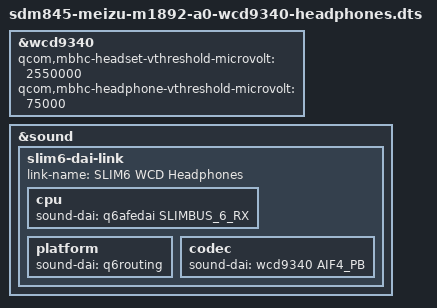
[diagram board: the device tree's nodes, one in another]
// SPDX-License-Identifier: GPL-2.0-only
/*
 * M1892 A0.7g: connect Multimedia1 to the stock Flyme headphone backend.
 *
 * Flyme 7.1.3.4A identifies the built-in 3.5-mm output as
 * SLIMBUS_6_RX -> WCD9340 AIF4_PB, using codec RX2/RX3.  Keep only that
 * playback backend in this diagnostic card so the SDM845 machine driver's
 * one-time SLIMbus channel-map setup is applied to AIF4, not AIF1.
 * Capture and both CS35L41 speaker amplifiers remain disabled.
 */

/dts-v1/;

#include <dt-bindings/sound/qcom,q6afe.h>
#include <dt-bindings/sound/qcom,wcd934x.h>

#include "sdm845-meizu-m1892-a0-minimal-card.dts"

&wcd9340 {
	/* Values measured from the stock M1892 downstream DT. */
	qcom,mbhc-headset-vthreshold-microvolt = <2550000>;
	qcom,mbhc-headphone-vthreshold-microvolt = <75000>;
};

&sound {
	slim6-dai-link {
		link-name = "SLIM6 WCD Headphones";

		cpu {
			sound-dai = <&q6afedai SLIMBUS_6_RX>;
		};

		platform {
			sound-dai = <&q6routing>;
		};

		codec {
			sound-dai = <&wcd9340 AIF4_PB>;
		};
	};
};
